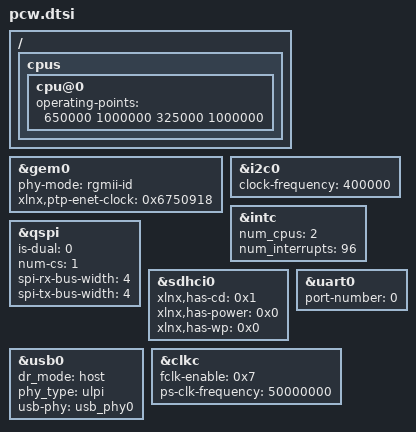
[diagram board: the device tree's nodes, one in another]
/*
 * CAUTION: This file is automatically generated by Xilinx.
 * Version:  
 * Today is: Thu Apr  9 12:48:12 2020
 */


/ {
	cpus {
		cpu@0 {
			operating-points = <650000 1000000 325000 1000000>;
		};
	};
};
&gem0 {
	phy-mode = "rgmii-id";
	status = "okay";
	xlnx,ptp-enet-clock = <0x6750918>;
};
&i2c0 {
	clock-frequency = <400000>;
	status = "okay";
};
&intc {
	num_cpus = <2>;
	num_interrupts = <96>;
};
&qspi {
	is-dual = <0>;
	num-cs = <1>;
	spi-rx-bus-width = <4>;
	spi-tx-bus-width = <4>;
	status = "okay";
};
&sdhci0 {
	status = "okay";
	xlnx,has-cd = <0x1>;
	xlnx,has-power = <0x0>;
	xlnx,has-wp = <0x0>;
};
&uart0 {
	device_type = "serial";
	port-number = <0>;
	status = "okay";
};
&usb0 {
	status = "okay";
	dr_mode = "host";
	phy_type = "ulpi";
	usb-phy = <&usb_phy0>;
};
&clkc {
	fclk-enable = <0x7>;
	ps-clk-frequency = <50000000>;
};
